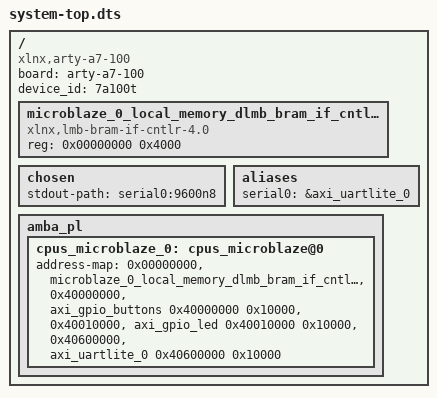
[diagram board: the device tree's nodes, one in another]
/dts-v1/;
#include "pl.dtsi"
/ {
	board = "arty-a7-100";
	compatible = "xlnx,arty-a7-100";
	device_id = "7a100t";
	#address-cells = <1>;
	#size-cells = <1>;
	microblaze_0_local_memory_dlmb_bram_if_cntlr_memory: memory@0 {
		compatible = "xlnx,lmb-bram-if-cntlr-4.0";
		device_type = "memory";
		reg = <0x00000000 0x4000>;
	};
	chosen {
		stdout-path = "serial0:9600n8";
	};
	aliases {
		serial0 = &axi_uartlite_0;
	};
	amba_pl: amba_pl {
		cpus_microblaze_0: cpus_microblaze@0 {
			address-map = <0x00000000 &microblaze_0_local_memory_dlmb_bram_if_cntlr_memory 0x00000000 0x4000>, 
			      <0x40000000 &axi_gpio_buttons 0x40000000 0x10000>, 
			      <0x40010000 &axi_gpio_led 0x40010000 0x10000>, 
			      <0x40600000 &axi_uartlite_0 0x40600000 0x10000>;
			#ranges-address-cells = <0x1>;
			#ranges-size-cells = <0x1>;
		};
	};
};
